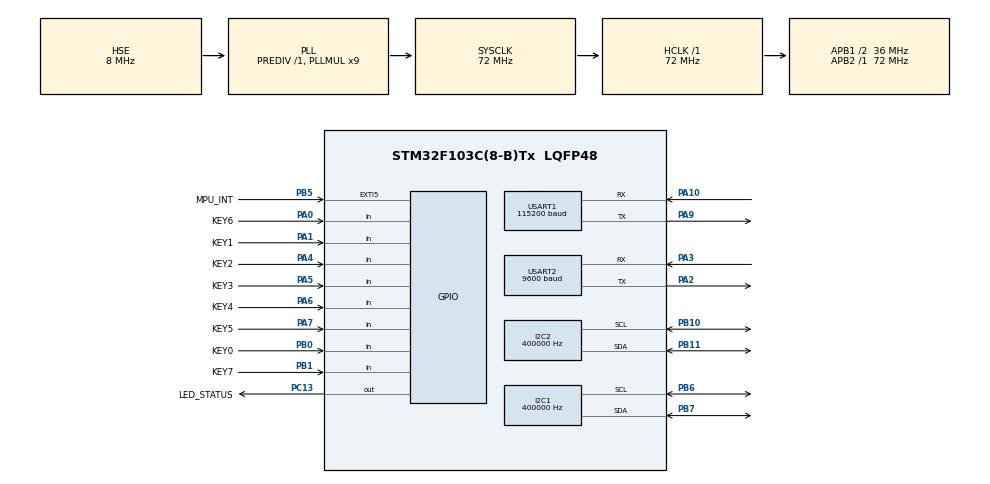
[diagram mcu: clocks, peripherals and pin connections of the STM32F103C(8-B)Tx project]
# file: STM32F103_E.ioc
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Dma.I2C2_TX.2.Direction=DMA_MEMORY_TO_PERIPH
Dma.I2C2_TX.2.Instance=DMA1_Channel4
Dma.I2C2_TX.2.MemDataAlignment=DMA_MDATAALIGN_BYTE
Dma.I2C2_TX.2.MemInc=DMA_MINC_ENABLE
Dma.I2C2_TX.2.Mode=DMA_NORMAL
Dma.I2C2_TX.2.PeriphDataAlignment=DMA_PDATAALIGN_BYTE
Dma.I2C2_TX.2.PeriphInc=DMA_PINC_DISABLE
Dma.I2C2_TX.2.Priority=DMA_PRIORITY_MEDIUM
Dma.Request0=USART2_RX
Dma.Request1=USART2_TX
Dma.Request2=I2C2_TX
Dma.USART2_RX.0.Direction=DMA_PERIPH_TO_MEMORY
Dma.USART2_RX.0.Instance=DMA1_Channel6
Dma.USART2_RX.0.MemDataAlignment=DMA_MDATAALIGN_BYTE
Dma.USART2_RX.0.MemInc=DMA_MINC_ENABLE
Dma.USART2_RX.0.Mode=DMA_CIRCULAR
Dma.USART2_RX.0.PeriphDataAlignment=DMA_PDATAALIGN_BYTE
Dma.USART2_RX.0.PeriphInc=DMA_PINC_DISABLE
Dma.USART2_RX.0.Priority=DMA_PRIORITY_HIGH
Dma.USART2_TX.1.Direction=DMA_MEMORY_TO_PERIPH
Dma.USART2_TX.1.Instance=DMA1_Channel7
Dma.USART2_TX.1.MemDataAlignment=DMA_MDATAALIGN_BYTE
Dma.USART2_TX.1.MemInc=DMA_MINC_ENABLE
Dma.USART2_TX.1.Mode=DMA_NORMAL
Dma.USART2_TX.1.PeriphDataAlignment=DMA_PDATAALIGN_BYTE
Dma.USART2_TX.1.PeriphInc=DMA_PINC_DISABLE
Dma.USART2_TX.1.Priority=DMA_PRIORITY_MEDIUM
I2C1.ClockSpeed=400000
I2C2.ClockSpeed=400000
IWDG.Prescaler=IWDG_PRESCALER_64
IWDG.Reload=2500
Mcu.Family=STM32F1
Mcu.Name=STM32F103C(8-B)Tx
Mcu.Package=LQFP48
NVIC.DMA1_Channel4_IRQn=true\:7\:0\:false\:false\:true\:false\:true\:true
NVIC.DMA1_Channel6_IRQn=true\:5\:0\:false\:false\:true\:false\:true\:true
NVIC.DMA1_Channel7_IRQn=true\:6\:0\:false\:false\:true\:false\:true\:true
NVIC.EXTI9_5_IRQn=true\:9\:0\:false\:false\:true\:true\:true\:true
NVIC.I2C2_ER_IRQn=true\:7\:0\:false\:false\:true\:true\:true\:true
NVIC.I2C2_EV_IRQn=true\:7\:0\:false\:false\:true\:true\:true\:true
NVIC.PriorityGroup=NVIC_PRIORITYGROUP_4
NVIC.USART1_IRQn=true\:8\:0\:false\:false\:true\:true\:true\:true
NVIC.USART2_IRQn=true\:5\:0\:false\:false\:true\:true\:true\:true
PA0-WKUP.GPIO_Label=KEY6
PA0-WKUP.GPIO_PuPd=GPIO_PULLUP
PA0-WKUP.Signal=GPIO_Input
PA1.GPIO_Label=KEY1
PA1.GPIO_PuPd=GPIO_PULLUP
PA1.Signal=GPIO_Input
PA10.Mode=Asynchronous
PA10.Signal=USART1_RX
PA13.Mode=Serial_Wire
PA13.Signal=SYS_JTMS-SWDIO
PA14.Mode=Serial_Wire
PA14.Signal=SYS_JTCK-SWCLK
PA2.Mode=Asynchronous
PA2.Signal=USART2_TX
PA3.Mode=Asynchronous
PA3.Signal=USART2_RX
PA4.GPIO_Label=KEY2
PA4.GPIO_PuPd=GPIO_PULLUP
PA4.Signal=GPIO_Input
PA5.GPIO_Label=KEY3
PA5.GPIO_PuPd=GPIO_PULLUP
PA5.Signal=GPIO_Input
PA6.GPIO_Label=KEY4
PA6.GPIO_PuPd=GPIO_PULLUP
PA6.Signal=GPIO_Input
PA7.GPIO_Label=KEY5
PA7.GPIO_PuPd=GPIO_PULLUP
PA7.Signal=GPIO_Input
PB0.GPIO_Label=KEY0
PB0.GPIO_PuPd=GPIO_PULLUP
PB0.Signal=GPIO_Input
PB1.GPIO_Label=KEY7
PB1.GPIO_PuPd=GPIO_PULLUP
PB1.Signal=GPIO_Input
PA9.Mode=Asynchronous
PA9.Signal=USART1_TX
PB10.Mode=I2C
PB10.Signal=I2C2_SCL
PB11.Mode=I2C
PB11.Signal=I2C2_SDA
PB5.GPIO_Label=MPU_INT
PB5.GPIO_ModeDefaultEXTI=GPIO_MODE_IT_FALLING
PB5.GPIO_PuPd=GPIO_PULLUP
PB5.Signal=GPXTI5
PB6.Mode=I2C
PB6.Signal=I2C1_SCL
PB7.Mode=I2C
PB7.Signal=I2C1_SDA
PC13-TAMPER-RTC.GPIO_Label=LED_STATUS
PC13-TAMPER-RTC.PinState=GPIO_PIN_SET
PC13-TAMPER-RTC.Signal=GPIO_Output
PD0-OSC_IN.Mode=HSE-External-Oscillator
PD0-OSC_IN.Signal=RCC_OSC_IN
PD1-OSC_OUT.Mode=HSE-External-Oscillator
PD1-OSC_OUT.Signal=RCC_OSC_OUT
ProjectManager.HeapSize=0x200
ProjectManager.StackSize=0x800
ProjectManager.TargetToolchain=STM32CubeIDE
RCC.AHBFreq_Value=72000000
RCC.APB1CLKDivider=RCC_HCLK_DIV2
RCC.APB1Freq_Value=36000000
RCC.APB1TimFreq_Value=72000000
RCC.APB2Freq_Value=72000000
RCC.APB2TimFreq_Value=72000000
RCC.HCLKFreq_Value=72000000
RCC.PLLMUL=RCC_PLL_MUL9
RCC.PLLSourceVirtual=RCC_PLLSOURCE_HSE
RCC.SYSCLKFreq_VALUE=72000000
RCC.SYSCLKSource=RCC_SYSCLKSOURCE_PLLCLK
USART1.BaudRate=115200
USART1.VirtualMode=VM_ASYNC
USART2.BaudRate=9600
USART2.VirtualMode=VM_ASYNC
VP_IWDG_VS_IWDG.Mode=IWDG_Activate
board=custom

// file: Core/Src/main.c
/* USER CODE BEGIN Header */
/**
  ******************************************************************************
  * @file           : main.c
  * @brief          : Main program body
  ******************************************************************************
  * @attention
  *
  * IMU-BLE Node 教學專案（STM32F103C8T6）
  *
  * 本檔為 CubeMX 產生之進入點；除 USER CODE 區塊外的內容重新產生時會被覆寫。
  * 應用程式真正的進入點在 Core/Src/app/app_main.c：
  *   - app_main_init() : 於周邊初始化完成後呼叫一次
  *   - app_main_loop() : 於主迴圈中反覆呼叫（協作式排程器）
  *
  ******************************************************************************
  */
/* USER CODE END Header */
#include "main.h"

/* USER CODE BEGIN Includes */
#include "app/app_main.h"
/* USER CODE END Includes */

I2C_HandleTypeDef hi2c1;
I2C_HandleTypeDef hi2c2;
DMA_HandleTypeDef hdma_i2c2_tx;

IWDG_HandleTypeDef hiwdg;

UART_HandleTypeDef huart1;
UART_HandleTypeDef huart2;
DMA_HandleTypeDef hdma_usart2_rx;
DMA_HandleTypeDef hdma_usart2_tx;

void SystemClock_Config(void);
static void MX_GPIO_Init(void);
static void MX_DMA_Init(void);
static void MX_I2C1_Init(void);
static void MX_I2C2_Init(void);
static void MX_USART1_UART_Init(void);
static void MX_USART2_UART_Init(void);
static void MX_IWDG_Init(void);

int main(void)
{

  /* MCU Configuration--------------------------------------------------------*/

  /* Reset of all peripherals, Initializes the Flash interface and the Systick. */
  HAL_Init();

  /* Configure the system clock */
  SystemClock_Config();

  /* USER CODE BEGIN SysInit */
  /* 除錯器連線時凍結 IWDG，避免中斷點停住時被看門狗重置；
   * 量產（無除錯器）狀態下看門狗照常生效。 */
  __HAL_DBGMCU_FREEZE_IWDG();
  /* USER CODE END SysInit */

  /* Initialize all configured peripherals */
  MX_GPIO_Init();
  MX_DMA_Init();
  MX_I2C1_Init();
  MX_I2C2_Init();
  MX_USART1_UART_Init();
  MX_USART2_UART_Init();
  MX_IWDG_Init();
  /* USER CODE BEGIN 2 */
  app_main_init();
  /* USER CODE END 2 */

  /* Infinite loop */
  while (1)
  {

    /* USER CODE BEGIN 3 */
    app_main_loop();
  }
  /* USER CODE END 3 */
}

void SystemClock_Config(void)
{
  RCC_OscInitTypeDef RCC_OscInitStruct = {0};
  RCC_ClkInitTypeDef RCC_ClkInitStruct = {0};

  /** Initializes the RCC Oscillators according to the specified parameters
  * in the RCC_OscInitTypeDef structure.
  */
  RCC_OscInitStruct.OscillatorType = RCC_OSCILLATORTYPE_HSE|RCC_OSCILLATORTYPE_LSI;
  RCC_OscInitStruct.HSEState = RCC_HSE_ON;
  RCC_OscInitStruct.HSEPredivValue = RCC_HSE_PREDIV_DIV1;
  RCC_OscInitStruct.HSIState = RCC_HSI_ON;
  RCC_OscInitStruct.LSIState = RCC_LSI_ON;
  RCC_OscInitStruct.PLL.PLLState = RCC_PLL_ON;
  RCC_OscInitStruct.PLL.PLLSource = RCC_PLLSOURCE_HSE;
  RCC_OscInitStruct.PLL.PLLMUL = RCC_PLL_MUL9;
  if (HAL_RCC_OscConfig(&RCC_OscInitStruct) != HAL_OK)
  {
    Error_Handler();
  }

  /** Initializes the CPU, AHB and APB buses clocks
  */
  RCC_ClkInitStruct.ClockType = RCC_CLOCKTYPE_HCLK|RCC_CLOCKTYPE_SYSCLK
                              |RCC_CLOCKTYPE_PCLK1|RCC_CLOCKTYPE_PCLK2;
  RCC_ClkInitStruct.SYSCLKSource = RCC_SYSCLKSOURCE_PLLCLK;
  RCC_ClkInitStruct.AHBCLKDivider = RCC_SYSCLK_DIV1;
  RCC_ClkInitStruct.APB1CLKDivider = RCC_HCLK_DIV2;
  RCC_ClkInitStruct.APB2CLKDivider = RCC_HCLK_DIV1;

  if (HAL_RCC_ClockConfig(&RCC_ClkInitStruct, FLASH_LATENCY_2) != HAL_OK)
  {
    Error_Handler();
  }
}

static void MX_I2C1_Init(void)
{

  hi2c1.Instance = I2C1;
  hi2c1.Init.ClockSpeed = 400000;
  hi2c1.Init.DutyCycle = I2C_DUTYCYCLE_2;
  hi2c1.Init.OwnAddress1 = 0;
  hi2c1.Init.AddressingMode = I2C_ADDRESSINGMODE_7BIT;
  hi2c1.Init.DualAddressMode = I2C_DUALADDRESS_DISABLE;
  hi2c1.Init.OwnAddress2 = 0;
  hi2c1.Init.GeneralCallMode = I2C_GENERALCALL_DISABLE;
  hi2c1.Init.NoStretchMode = I2C_NOSTRETCH_DISABLE;
  if (HAL_I2C_Init(&hi2c1) != HAL_OK)
  {
    Error_Handler();
  }

}

static void MX_I2C2_Init(void)
{

  hi2c2.Instance = I2C2;
  hi2c2.Init.ClockSpeed = 400000;
  hi2c2.Init.DutyCycle = I2C_DUTYCYCLE_2;
  hi2c2.Init.OwnAddress1 = 0;
  hi2c2.Init.AddressingMode = I2C_ADDRESSINGMODE_7BIT;
  hi2c2.Init.DualAddressMode = I2C_DUALADDRESS_DISABLE;
  hi2c2.Init.OwnAddress2 = 0;
  hi2c2.Init.GeneralCallMode = I2C_GENERALCALL_DISABLE;
  hi2c2.Init.NoStretchMode = I2C_NOSTRETCH_DISABLE;
  if (HAL_I2C_Init(&hi2c2) != HAL_OK)
  {
    Error_Handler();
  }

}

static void MX_IWDG_Init(void)
{

  /* USER CODE BEGIN IWDG_Init 1 */
  /* LSI 約 40kHz（誤差可達 ±50%），/64 後 625Hz，Reload=2500 → 名目 4 秒逾時。
   * 韌體於 task_sys 中確認所有關鍵任務均有簽到後才餵狗。 */
  /* USER CODE END IWDG_Init 1 */
  hiwdg.Instance = IWDG;
  hiwdg.Init.Prescaler = IWDG_PRESCALER_64;
  hiwdg.Init.Reload = 2500;
  if (HAL_IWDG_Init(&hiwdg) != HAL_OK)
  {
    Error_Handler();
  }

}

static void MX_USART1_UART_Init(void)
{

  huart1.Instance = USART1;
  huart1.Init.BaudRate = 115200;
  huart1.Init.WordLength = UART_WORDLENGTH_8B;
  huart1.Init.StopBits = UART_STOPBITS_1;
  huart1.Init.Parity = UART_PARITY_NONE;
  huart1.Init.Mode = UART_MODE_TX_RX;
  huart1.Init.HwFlowCtl = UART_HWCONTROL_NONE;
  huart1.Init.OverSampling = UART_OVERSAMPLING_16;
  if (HAL_UART_Init(&huart1) != HAL_OK)
  {
    Error_Handler();
  }

}

static void MX_USART2_UART_Init(void)
{

  huart2.Instance = USART2;
  huart2.Init.BaudRate = 9600;
  huart2.Init.WordLength = UART_WORDLENGTH_8B;
  huart2.Init.StopBits = UART_STOPBITS_1;
  huart2.Init.Parity = UART_PARITY_NONE;
  huart2.Init.Mode = UART_MODE_TX_RX;
  huart2.Init.HwFlowCtl = UART_HWCONTROL_NONE;
  huart2.Init.OverSampling = UART_OVERSAMPLING_16;
  if (HAL_UART_Init(&huart2) != HAL_OK)
  {
    Error_Handler();
  }

}

static void MX_DMA_Init(void)
{

  /* DMA controller clock enable */
  __HAL_RCC_DMA1_CLK_ENABLE();

  /* DMA interrupt init */
  /* DMA1_Channel4_IRQn interrupt configuration */
  HAL_NVIC_SetPriority(DMA1_Channel4_IRQn, 7, 0);
  HAL_NVIC_EnableIRQ(DMA1_Channel4_IRQn);
  /* DMA1_Channel6_IRQn interrupt configuration */
  HAL_NVIC_SetPriority(DMA1_Channel6_IRQn, 5, 0);
  HAL_NVIC_EnableIRQ(DMA1_Channel6_IRQn);
  /* DMA1_Channel7_IRQn interrupt configuration */
  HAL_NVIC_SetPriority(DMA1_Channel7_IRQn, 6, 0);
  HAL_NVIC_EnableIRQ(DMA1_Channel7_IRQn);

}

static void MX_GPIO_Init(void)
{
  GPIO_InitTypeDef GPIO_InitStruct = {0};

  /* GPIO Ports Clock Enable */
  __HAL_RCC_GPIOC_CLK_ENABLE();
  __HAL_RCC_GPIOD_CLK_ENABLE();
  __HAL_RCC_GPIOA_CLK_ENABLE();
  __HAL_RCC_GPIOB_CLK_ENABLE();

  /*Configure GPIO pin Output Level */
  HAL_GPIO_WritePin(LED_STATUS_GPIO_Port, LED_STATUS_Pin, GPIO_PIN_SET);

  /*Configure GPIO pin : LED_STATUS_Pin */
  GPIO_InitStruct.Pin = LED_STATUS_Pin;
  GPIO_InitStruct.Mode = GPIO_MODE_OUTPUT_PP;
  GPIO_InitStruct.Speed = GPIO_SPEED_FREQ_LOW;
  HAL_GPIO_Init(LED_STATUS_GPIO_Port, &GPIO_InitStruct);

  /*Configure GPIO pins : KEY6_Pin KEY1_Pin KEY2_Pin KEY3_Pin
                           KEY4_Pin KEY5_Pin */
  GPIO_InitStruct.Pin = KEY6_Pin|KEY1_Pin|KEY2_Pin|KEY3_Pin
                          |KEY4_Pin|KEY5_Pin;
  GPIO_InitStruct.Mode = GPIO_MODE_INPUT;
  GPIO_InitStruct.Pull = GPIO_PULLUP;
  HAL_GPIO_Init(GPIOA, &GPIO_InitStruct);

  /*Configure GPIO pins : KEY0_Pin KEY7_Pin */
  GPIO_InitStruct.Pin = KEY0_Pin|KEY7_Pin;
  GPIO_InitStruct.Mode = GPIO_MODE_INPUT;
  GPIO_InitStruct.Pull = GPIO_PULLUP;
  HAL_GPIO_Init(GPIOB, &GPIO_InitStruct);

  /*Configure GPIO pin : MPU_INT_Pin */
  GPIO_InitStruct.Pin = MPU_INT_Pin;
  GPIO_InitStruct.Mode = GPIO_MODE_IT_FALLING;
  GPIO_InitStruct.Pull = GPIO_PULLUP;
  HAL_GPIO_Init(MPU_INT_GPIO_Port, &GPIO_InitStruct);

  /* EXTI interrupt init*/
  HAL_NVIC_SetPriority(EXTI9_5_IRQn, 9, 0);
  HAL_NVIC_EnableIRQ(EXTI9_5_IRQn);

}

void Error_Handler(void)
{
  /* USER CODE BEGIN Error_Handler_Debug */
  /* 初始化階段的致命錯誤：停用中斷後停住，方便除錯器接上檢視現場。
   * 量產環境下 IWDG 未餵狗約 4 秒後會觸發硬體重置，系統可自行復原。 */
  __disable_irq();
  while (1)
  {
  }
  /* USER CODE END Error_Handler_Debug */
}

#ifdef  USE_FULL_ASSERT
/**
  * @brief  Reports the name of the source file and the source line number
  *         where the assert_param error has occurred.
  * @param  file: pointer to the source file name
  * @param  line: assert_param error line source number
  * @retval None
  */
void assert_failed(uint8_t *file, uint32_t line)
{
  /* USER CODE BEGIN 6 */
  (void)file;
  (void)line;
  /* USER CODE END 6 */
}
#endif /* USE_FULL_ASSERT */
